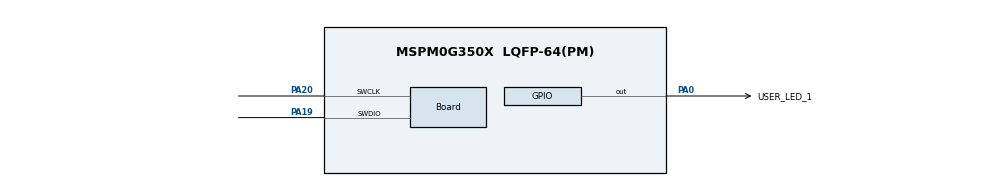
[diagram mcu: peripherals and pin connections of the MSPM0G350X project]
/**
 * @cliArgs --device "MSPM0G350X" --package "LQFP-64(PM)" --part "Default" --product "mspm0_sdk@2.01.00.03"
 * @versions {"tool":"1.20.0+3587"}
 */

/**
 * Import the modules used in this configuration.
 */
const Board         = scripting.addModule("/ti/driverlib/Board");
const GPIO          = scripting.addModule("/ti/driverlib/GPIO", {}, false);
const GPIO1         = GPIO.addInstance();
const GPIO2         = GPIO.addInstance();
const GPIO3         = GPIO.addInstance();
const SYSCTL        = scripting.addModule("/ti/driverlib/SYSCTL");
const TIMER         = scripting.addModule("/ti/driverlib/TIMER", {}, false);
const TIMER1        = TIMER.addInstance();
const ProjectConfig = scripting.addModule("/ti/project_config/ProjectConfig");

/**
 * Write custom configuration values to the imported modules.
 */
Board.peripheral.$assign          = "DEBUGSS";
Board.peripheral.swclkPin.$assign = "PA20";
Board.peripheral.swdioPin.$assign = "PA19";

GPIO1.port                           = "PORTA";
GPIO1.$name                          = "GPIO_LEDS_PORT";
GPIO1.portSegment                    = "Lower";
GPIO1.associatedPins[0].initialValue = "SET";
GPIO1.associatedPins[0].$name        = "USER_LED_1";
GPIO1.associatedPins[0].assignedPin  = "0";
GPIO1.associatedPins[0].pin.$assign  = "PA0";

GPIO2.$name                         = "GPIO_RGB";
GPIO2.port                          = "PORTB";
GPIO2.portSegment                   = "Upper";
GPIO2.associatedPins.create(3);
GPIO2.associatedPins[0].$name       = "RED";
GPIO2.associatedPins[0].assignedPin = "26";
GPIO2.associatedPins[1].$name       = "GREEN";
GPIO2.associatedPins[1].assignedPin = "27";
GPIO2.associatedPins[2].$name       = "BLUE";
GPIO2.associatedPins[2].assignedPin = "22";

GPIO3.$name                                 = "GPIO_KEY";
GPIO3.associatedPins.create(3);
GPIO3.associatedPins[0].$name               = "KEY_1";
GPIO3.associatedPins[0].direction           = "INPUT";
GPIO3.associatedPins[0].assignedPort        = "PORTB";
GPIO3.associatedPins[0].assignedPortSegment = "Upper";
GPIO3.associatedPins[0].assignedPin         = "21";
GPIO3.associatedPins[1].assignedPin         = "23";
GPIO3.associatedPins[1].$name               = "KEY_2";
GPIO3.associatedPins[1].direction           = "INPUT";
GPIO3.associatedPins[1].assignedPort        = "PORTB";
GPIO3.associatedPins[1].assignedPortSegment = "Upper";
GPIO3.associatedPins[2].assignedPin         = "24";
GPIO3.associatedPins[2].$name               = "KEY_3";
GPIO3.associatedPins[2].direction           = "INPUT";
GPIO3.associatedPins[2].assignedPort        = "PORTB";
GPIO3.associatedPins[2].assignedPortSegment = "Upper";

SYSCTL.clockTreeEn = true;

TIMER1.$name              = "TIMER_0";
TIMER1.interrupts         = ["ZERO"];
TIMER1.timerMode          = "PERIODIC";
TIMER1.timerPeriod        = "1ms";
TIMER1.peripheral.$assign = "TIMG0";

ProjectConfig.deviceSpin = "MSPM0G3507";

/**
 * Pinmux solution for unlocked pins/peripherals. This ensures that minor changes to the automatic solver in a future
 * version of the tool will not impact the pinmux you originally saw.  These lines can be completely deleted in order to
 * re-solve from scratch.
 */
GPIO2.associatedPins[0].pin.$suggestSolution = "PB26";
GPIO2.associatedPins[1].pin.$suggestSolution = "PB27";
GPIO2.associatedPins[2].pin.$suggestSolution = "PB22";
GPIO3.associatedPins[0].pin.$suggestSolution = "PB21";
GPIO3.associatedPins[1].pin.$suggestSolution = "PB23";
GPIO3.associatedPins[2].pin.$suggestSolution = "PB24";
